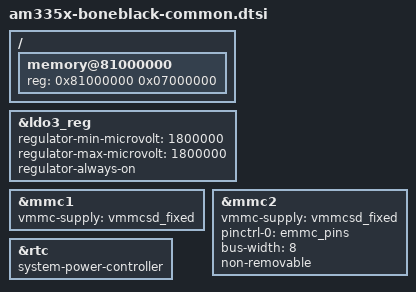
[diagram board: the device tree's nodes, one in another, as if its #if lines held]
// SPDX-License-Identifier: GPL-2.0-only
/*
 * Copyright (C) 2012 Texas Instruments Incorporated - https://www.ti.com/
 */

&ldo3_reg {
	regulator-min-microvolt = <1800000>;
	regulator-max-microvolt = <1800000>;
	regulator-always-on;
};

&mmc1 {
	vmmc-supply = <&vmmcsd_fixed>;
};

&mmc2 {
	vmmc-supply = <&vmmcsd_fixed>;
	pinctrl-names = "default";
	pinctrl-0 = <&emmc_pins>;
	bus-width = <8>;
	status = "okay";
	non-removable;
};

&rtc {
	system-power-controller;
};

/ {
#ifdef CONFIG_TRUSTFULL_HYPERVISOR
	memory@81000000 {
#else
	memory@81000000 {
//	memory@80000000 {
#endif
		device_type = "memory";
#ifdef CONFIG_TRUSTFULL_HYPERVISOR
		reg = <0x81000000 0x07000000>; /* 112 MB */
#else
		reg = <0x81000000 0x07000000>; /* 112 MB */
//		reg = <0x80000000 0x20000000>; /* 512 MB */
#endif
	};
};
